# lm3s9b92 register map
Vendor: Texas Instruments Inc.; Series: LM3S; File version: 1.2
ARM Cortex-M3 Stellaris Device
CPU: CM3 r2p0, little endian, no MPU, no FPU, 3 interrupt priority bits
Registers are 32-bit, read-write, reset 0x0 unless marked. A register's access mark holds for its fields unless they carry their own. Offsets are from the block's base; lines under a group give offsets from that group; [hi:lo] are bit positions; {n}, {i} and the like mark numbered series; 'fields as' and 'values as' point back to an identical list; <NAME> marks a mode.

## Memory map
0x40000000 WDT0 size 0x1000 — Watchdog timer 0, with 32-bit down counter.
0x40001000 WDT1 size 0x1000
0x40004000 GPIOA size 0x1000 — Register map for GPIO PORT A peripheral.
0x40005000 GPIOB size 0x1000
0x40006000 GPIOC size 0x1000
0x40007000 GPIOD size 0x1000
0x40024000 GPIOE size 0x1000
0x40025000 GPIOF size 0x1000
0x40026000 GPIOG size 0x1000
0x40027000 GPIOH size 0x1000
0x4003D000 GPIOJ size 0x1000
0x400FE000 SYSCTL size 0x1A4 — System control configures the overall operation of the device and provides information about the device.

## Interrupts
0 GPIOA — GPIO A interrupt.
1 GPIOB — GPIO B interrupt.
2 GPIOC — GPIO C interrupt.
3 GPIOD — GPIO D interrupt.
4 GPIOE — GPIO E interrupt.
18 WDT0 — Watchdog Timer 0 and 1 interrupt.
28 SYSCTL — System Control interrupt.
30 GPIOF — GPIO F interrupt.
31 GPIOG — GPIO G interrupt.
32 GPIOH — GPIO H interrupt.
54 GPIOJ — GPIO J interrupt.

## WDT0 — Watchdog timer 0, with 32-bit down counter.
Base 0x40000000
Same registers: WDT1 0x40001000
0x00 WDTLOAD reset 0xFFFFFFFF — 32-bit interval value used by the 32-bit watchdog down-counter.
0x04 WDTVALUE reset 0xFFFFFFFF — 32-bit register with the current count value of the timer.
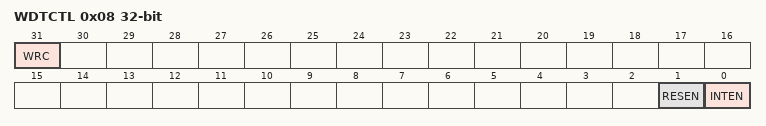
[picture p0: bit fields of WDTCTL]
0x08 WDTCTL — Watchdog Control Register.
  [31] WRC ro — Watchdog Timer Write Complete
    0=Busy (A write access to one of the WDT1 registers is in progress.); 1=Ready (A write access is not in progress, and WDT registers can be read or written.)
  [1] RESEN — Watchdog Reset Enable
    0=Disabled (Watchdog Timer reset output is disabled.); 1=Enabled (Watchdog Timer reset output is enabled.)
  [0] INTEN — Watchdog Interrupt Enable
    0=Disabled (Watchdog Timer interrupt event is disabled (once this bit is set, it can only be cleared by a hardware reset).); 1=Enabled (Watchdog Timer interrupt event enabled. Once enabled, all writes are ignored.)
0x0C ICR wo reset not defined — Watchdog Interrupt Clear Register.
0x10 RIS — Watchdog Raw Interrupt Status Register.
  [0] WDTRIS ro — Watchdog Raw Interrupt Status
    0=Reset (The watchdog has not timed out.); 1=Set (A watchdog time-out event has occurred.)
0x14 WDTMIS — Watchdog Masked Interrupt Status Register.
  [0] WDTMIS ro — Watchdog Masked Interrupt Status.
    0=Reset (The watchdog has not timed out or the watchdog timer interrupt is masked.); 1=Set (A watchdog time-out event has been signalled to the interrupt controller.)
0x418 WDTTEST (reset mask 0x1000) — Watchdog Test Register.
  [8] STALL — Watchdog Stall Enable.
    0=Disabled (If the microcontroller is stopped with a debugger, the watchdog timer stops counting. Once the microcontroller is restarted, the watchdog timer resumes counting.); 1=Enabled (The watchdog timer continues counting if the microcontroller is stopped with a debugger.)
0xC00 WDTLOCK — Watchdog Lock Register.
  [0] WDTLOCK — Watchdog Lock
    on read: 0=Unlocked (Watchdog registers are unlocked for write access.); 1=Locked (Watchdog registers are locked for write access.)

## Licence text in the file
Redistribution and use in source and binary forms, with or without modification, are permitted provided that the following conditions are met: . Redistributions of source code must retain the above copyright notice, this list of conditions and the following disclaimer. . Redistributions in binary form must reproduce the above copyright notice, this list of conditions and the following disclaimer listed in this license in the documentation and/or other materials provided with the distribution. . Neither the name of the copyright holders nor the names of its contributors may be used to endorse or promote products derived from this software without specific prior written permission. . The copyright holders provide no reassurances that the source code provided does not infringe any patent, copyright, or any other intellectual property rights of third parties. The copyright holders disclaim any liability to any recipient for claims brought against recipient by any third party for infringement of that parties intellectual property rights. . THIS SOFTWARE IS PROVIDED BY THE COPYRIGHT HOLDERS AND CONTRIBUTORS “AS IS” AND ANY EXPRESS OR IMPLIED WARRANTIES, INCLUDING, BUT NOT. LIMITED TO, THE IMPLIED WARRANTIES OF MERCHANTABILITY AND FITNESS FOR. A PARTICULAR PURPOSE ARE DISCLAIMED. IN NO EVENT SHALL THE COPYRIGHT. OWNER OR CONTRIBUTORS BE LIABLE FOR ANY DIRECT, INDIRECT, INCIDENTAL, SPECIAL, EXEMPLARY, OR CONSEQUENTIAL DAMAGES (INCLUDING, BUT NOT. LIMITED TO, PROCUREMENT OF SUBSTITUTE GOODS OR SERVICES; LOSS OF USE, DATA, OR PROFITS; OR BUSINESS INTERRUPTION) HOWEVER CAUSED AND ON ANY. THEORY OF LIABILITY, WHETHER IN CONTRACT, STRICT LIABILITY, OR TORT (INCLUDING NEGLIGENCE OR OTHERWISE) ARISING IN ANY WAY OUT OF THE USE. OF THIS SOFTWARE, EVEN IF ADVISED OF THE POSSIBILITY OF SUCH DAMAGE.

## Notices in the file
Copyright (c) 2026, MaxFlatline
All rights reserved.
[Full BSD-3-Clause license text - See https://opensource.org]
SPDX-License-Identifier: BSD-3-Clause
